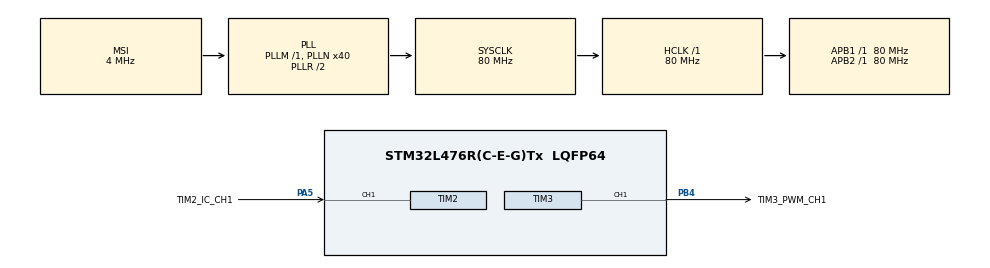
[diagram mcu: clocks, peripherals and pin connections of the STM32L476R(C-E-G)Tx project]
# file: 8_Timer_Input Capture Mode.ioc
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Mcu.Family=STM32L4
Mcu.Name=STM32L476R(C-E-G)Tx
Mcu.Package=LQFP64
NVIC.PriorityGroup=NVIC_PRIORITYGROUP_4
NVIC.TIM2_IRQn=true\:0\:0\:false\:false\:true\:true\:true\:true
PA5.GPIO_Label=TIM2_IC_CH1
PA5.Signal=S_TIM2_CH1
PB4\ (NJTRST).GPIO_Label=TIM3_PWM_CH1
PB4\ (NJTRST).Signal=S_TIM3_CH1
ProjectManager.HeapSize=0x200
ProjectManager.StackSize=0x400
ProjectManager.TargetToolchain=STM32CubeIDE
RCC.AHBFreq_Value=80000000
RCC.APB1Freq_Value=80000000
RCC.APB1TimFreq_Value=80000000
RCC.APB2Freq_Value=80000000
RCC.APB2TimFreq_Value=80000000
RCC.CortexFreq_Value=80000000
RCC.HCLKFreq_Value=80000000
RCC.HSE_VALUE=8000000
RCC.HSI_VALUE=16000000
RCC.LSE_VALUE=32768
RCC.MSI_VALUE=4000000
RCC.PLLN=40
RCC.SYSCLKFreq_VALUE=80000000
RCC.SYSCLKSource=RCC_SYSCLKSOURCE_PLLCLK
RCC.VCOOutputFreq_Value=160000000
SH.S_TIM2_CH1.0=TIM2_CH1,Input_Capture1_from_TI1
SH.S_TIM3_CH1.0=TIM3_CH1,PWM Generation1 CH1
TIM2.Channel-Input_Capture1_from_TI1=TIM_CHANNEL_1
TIM2.Period=4294967295
TIM2.Prescaler=80-1
TIM3.Channel-PWM\ Generation1\ CH1=TIM_CHANNEL_1
TIM3.Period=1000
TIM3.Prescaler=79
TIM3.Pulse-PWM\ Generation1\ CH1=500
VP_TIM2_VS_ClockSourceINT.Mode=Internal
VP_TIM3_VS_ClockSourceINT.Mode=Internal
board=custom

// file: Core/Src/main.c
/* USER CODE BEGIN Header */
/**
  ******************************************************************************
  * @file           : main.c
  * @brief          : Main program body
  ******************************************************************************
  * @attention
  *
  * Copyright (c) 2023 STMicroelectronics.
  * All rights reserved.
  *
  * This software is licensed under terms that can be found in the LICENSE file
  * in the root directory of this software component.
  * If no LICENSE file comes with this software, it is provided AS-IS.
  *
  ******************************************************************************
  */

  /****************************************************************************
	This project could serve the following functionalities according to the Input capture configuration
	for Timer 2:

	- Compute PWM Frequency generated by Timer 3 for that you should
	  1_ Set Timer 2 polarity to rising edge:
	     sConfigIC.ICPolarity = TIM_INPUTCHANNELPOLARITY_RISING;
	  2_ Use the IC_callback function as follows:
	  	 void HAL_TIM_IC_CaptureCallback(TIM_HandleTypeDef *htim)
{
	x+=1;
	if (htim->Channel == HAL_TIM_ACTIVE_CHANNEL_1)
	{
		if (Is_First_Captured==0) // if the first rising edge is not captured
		{
			IC_Val1 = HAL_TIM_ReadCapturedValue(htim, TIM_CHANNEL_1); // read the first value
			Is_First_Captured = 1;  // set the first captured as true
		}

		else   // If the first rising edge is captured, now we will capture the second edge
		{
			IC_Val2 = HAL_TIM_ReadCapturedValue(htim, TIM_CHANNEL_1);  // read second value

			if (IC_Val2 > IC_Val1)
			{
				Difference = IC_Val2-IC_Val1;
			}

			else if (IC_Val1 > IC_Val2)
			{
				Difference = (0xffffffff - IC_Val1) + IC_Val2; // or we can use: Difference = abs(IC_Val2-IC_Val1) without the if and else conditions
			}

			float refClock = TIM2_CLK/(TIM2_PRESCALER + 1);

			frequency = refClock/Difference; //// Cause PWM_Periode = TIM tick delay(period) * (Timer2 Second Captured tick value - Timer2 First Captured tick value)

			__HAL_TIM_SET_COUNTER(htim, 0);  // reset the counter
			Is_First_Captured = 0; // set it back to false
		}
	}
}

	- Compute PWM "ON" width (or duty cycle) generated by Timer 3 for that you should
		1_ Set Timer 2 polarity to both edges:
			sConfigIC.ICPolarity = TIM_INPUTCHANNELPOLARITY_BOTHEDGE;
		2_ Use the previous IC_callback function as follows:
	  	 void HAL_TIM_IC_CaptureCallback(TIM_HandleTypeDef *htim)
{
	x+=1;
	if (htim->Channel == HAL_TIM_ACTIVE_CHANNEL_1)
	{
		if (Is_First_Captured==0) // if the first rising edge is captured
		{
			IC_Val1 = HAL_TIM_ReadCapturedValue(htim, TIM_CHANNEL_1); // read the first value
			Is_First_Captured = 1;  // set the first captured as true
		}

		else   // If the first rising edge is already captured, now we will capture the second edge
		{
			IC_Val2 = HAL_TIM_ReadCapturedValue(htim, TIM_CHANNEL_1);  // read second value

			if (IC_Val2 > IC_Val1)
			{
				Difference = IC_Val2-IC_Val1;
			}

			else if (IC_Val1 > IC_Val2)
			{
				Difference = (0xffffffff - IC_Val1) + IC_Val2; // or we can use: Difference = abs(IC_Val2-IC_Val1) without the if and else conditions
			}

			float ref_period = (TIM2_PRESCALER + 1)/TIM2_CLK;

			ON_width = ref_period*Difference; //// Cause PWM_Periode = TIM tick delay(period) * (Timer2 Second Captured tick value - Timer2 First Captured tick value)
			Duty_cycle = Difference / TIM2->ARR // here we are computing the duty cycle.

			__HAL_TIM_SET_COUNTER(htim, 0);  // reset the counter
			Is_First_Captured = 0; // set it back to false
		}
	}
}

 PS:
 - In both techniques we can set timer counter to 0 once we get the first trigger
 Then capture the counter value in the second input capture trigger.
 - Note that using Input PWM mode (Combined channels section in CubeMX) on Timer 2 ensure measuring the PWM signal width and frequency
 with the same configuration. Refer to this tutorial: https://www.youtube.com/watch?v=P6211ic2N_s&list=PLfIJKC1ud8gjLZBzjE3kKBMDEH_lUc428&index=4

  ******************************************************************************
  */

/* USER CODE END Header */
#include "main.h"

TIM_HandleTypeDef htim2;
TIM_HandleTypeDef htim3;

/* USER CODE BEGIN PV */
#define TIM2_CLK 8000000 // TIM2_CLK
#define TIM2_PRESCALER 79 // TIM2_PRE
int count = 0;

//Those parameters are set constant and they will serve reference frequency calculation (TIM2 frequency) according to : Frequency = TIM2_CLK / (1 + TIM2_PRE)

//We are using Timer2 in input capture mode to compute an external frequency (Timer3)

/* USER CODE END PV */

void SystemClock_Config(void);
static void MX_GPIO_Init(void);
static void MX_TIM2_Init(void);
static void MX_TIM3_Init(void);
/* USER CODE BEGIN PFP */

//HAL_TIM_IC_CaptureCallback function declaration

void HAL_TIM_IC_CaptureCallback( TIM_HandleTypeDef *htim );

/* USER CODE END PFP */

int main(void)
{

  /* MCU Configuration--------------------------------------------------------*/

  /* Reset of all peripherals, Initializes the Flash interface and the Systick. */
  HAL_Init();

  /* Configure the system clock */
  SystemClock_Config();

  /* Initialize all configured peripherals */
  MX_GPIO_Init();
  MX_TIM2_Init();
  MX_TIM3_Init();
  /* USER CODE BEGIN 2 */
  HAL_TIM_PWM_Start(&htim3, TIM_CHANNEL_1);// Lunch the Timer 3 generating PWM signal with a fix duty cycle = 0.5 and a frequency set to 1Mhz
  HAL_TIM_IC_Start(&htim2, TIM_CHANNEL_1);// Start the timer 2 responsible of capturing the rising edges of the generated PWM signal using the
  //Callback function. Which will enable frequency calculation according to the following equation: frequency  = ref_frequency/(First_Rising-Second_Rising)

  /* USER CODE END 2 */

  /* Infinite loop */
  while (1)
  {

  }
}

void SystemClock_Config(void)
{
  RCC_OscInitTypeDef RCC_OscInitStruct = {0};
  RCC_ClkInitTypeDef RCC_ClkInitStruct = {0};

  /** Configure the main internal regulator output voltage
  */
  if (HAL_PWREx_ControlVoltageScaling(PWR_REGULATOR_VOLTAGE_SCALE1) != HAL_OK)
  {
    Error_Handler();
  }

  /** Initializes the RCC Oscillators according to the specified parameters
  * in the RCC_OscInitTypeDef structure.
  */
  RCC_OscInitStruct.OscillatorType = RCC_OSCILLATORTYPE_MSI;
  RCC_OscInitStruct.MSIState = RCC_MSI_ON;
  RCC_OscInitStruct.MSICalibrationValue = 0;
  RCC_OscInitStruct.MSIClockRange = RCC_MSIRANGE_6;
  RCC_OscInitStruct.PLL.PLLState = RCC_PLL_ON;
  RCC_OscInitStruct.PLL.PLLSource = RCC_PLLSOURCE_MSI;
  RCC_OscInitStruct.PLL.PLLM = 1;
  RCC_OscInitStruct.PLL.PLLN = 40;
  RCC_OscInitStruct.PLL.PLLP = RCC_PLLP_DIV7;
  RCC_OscInitStruct.PLL.PLLQ = RCC_PLLQ_DIV2;
  RCC_OscInitStruct.PLL.PLLR = RCC_PLLR_DIV2;
  if (HAL_RCC_OscConfig(&RCC_OscInitStruct) != HAL_OK)
  {
    Error_Handler();
  }

  /** Initializes the CPU, AHB and APB buses clocks
  */
  RCC_ClkInitStruct.ClockType = RCC_CLOCKTYPE_HCLK|RCC_CLOCKTYPE_SYSCLK
                              |RCC_CLOCKTYPE_PCLK1|RCC_CLOCKTYPE_PCLK2;
  RCC_ClkInitStruct.SYSCLKSource = RCC_SYSCLKSOURCE_PLLCLK;
  RCC_ClkInitStruct.AHBCLKDivider = RCC_SYSCLK_DIV1;
  RCC_ClkInitStruct.APB1CLKDivider = RCC_HCLK_DIV1;
  RCC_ClkInitStruct.APB2CLKDivider = RCC_HCLK_DIV1;

  if (HAL_RCC_ClockConfig(&RCC_ClkInitStruct, FLASH_LATENCY_4) != HAL_OK)
  {
    Error_Handler();
  }
}

static void MX_TIM2_Init(void)
{

  TIM_ClockConfigTypeDef sClockSourceConfig = {0};
  TIM_MasterConfigTypeDef sMasterConfig = {0};
  TIM_IC_InitTypeDef sConfigIC = {0};

  htim2.Instance = TIM2;
  htim2.Init.Prescaler = 80-1;
  htim2.Init.CounterMode = TIM_COUNTERMODE_UP;
  htim2.Init.Period = 4294967295;
  htim2.Init.ClockDivision = TIM_CLOCKDIVISION_DIV1;
  htim2.Init.AutoReloadPreload = TIM_AUTORELOAD_PRELOAD_DISABLE;
  if (HAL_TIM_Base_Init(&htim2) != HAL_OK)
  {
    Error_Handler();
  }
  sClockSourceConfig.ClockSource = TIM_CLOCKSOURCE_INTERNAL;
  if (HAL_TIM_ConfigClockSource(&htim2, &sClockSourceConfig) != HAL_OK)
  {
    Error_Handler();
  }
  if (HAL_TIM_IC_Init(&htim2) != HAL_OK)
  {
    Error_Handler();
  }
  sMasterConfig.MasterOutputTrigger = TIM_TRGO_RESET;
  sMasterConfig.MasterSlaveMode = TIM_MASTERSLAVEMODE_DISABLE;
  if (HAL_TIMEx_MasterConfigSynchronization(&htim2, &sMasterConfig) != HAL_OK)
  {
    Error_Handler();
  }
  sConfigIC.ICPolarity = TIM_INPUTCHANNELPOLARITY_RISING;
  sConfigIC.ICSelection = TIM_ICSELECTION_DIRECTTI;
  sConfigIC.ICPrescaler = TIM_ICPSC_DIV1;
  sConfigIC.ICFilter = 0;
  if (HAL_TIM_IC_ConfigChannel(&htim2, &sConfigIC, TIM_CHANNEL_1) != HAL_OK)
  {
    Error_Handler();
  }

}

static void MX_TIM3_Init(void)
{

  TIM_ClockConfigTypeDef sClockSourceConfig = {0};
  TIM_MasterConfigTypeDef sMasterConfig = {0};
  TIM_OC_InitTypeDef sConfigOC = {0};

  htim3.Instance = TIM3;
  htim3.Init.Prescaler = 79;
  htim3.Init.CounterMode = TIM_COUNTERMODE_UP;
  htim3.Init.Period = 1000;
  htim3.Init.ClockDivision = TIM_CLOCKDIVISION_DIV1;
  htim3.Init.AutoReloadPreload = TIM_AUTORELOAD_PRELOAD_DISABLE;
  if (HAL_TIM_Base_Init(&htim3) != HAL_OK)
  {
    Error_Handler();
  }
  sClockSourceConfig.ClockSource = TIM_CLOCKSOURCE_INTERNAL;
  if (HAL_TIM_ConfigClockSource(&htim3, &sClockSourceConfig) != HAL_OK)
  {
    Error_Handler();
  }
  if (HAL_TIM_PWM_Init(&htim3) != HAL_OK)
  {
    Error_Handler();
  }
  sMasterConfig.MasterOutputTrigger = TIM_TRGO_RESET;
  sMasterConfig.MasterSlaveMode = TIM_MASTERSLAVEMODE_DISABLE;
  if (HAL_TIMEx_MasterConfigSynchronization(&htim3, &sMasterConfig) != HAL_OK)
  {
    Error_Handler();
  }
  sConfigOC.OCMode = TIM_OCMODE_PWM1;
  sConfigOC.Pulse = 500;
  sConfigOC.OCPolarity = TIM_OCPOLARITY_HIGH;
  sConfigOC.OCFastMode = TIM_OCFAST_DISABLE;
  if (HAL_TIM_PWM_ConfigChannel(&htim3, &sConfigOC, TIM_CHANNEL_1) != HAL_OK)
  {
    Error_Handler();
  }
  HAL_TIM_MspPostInit(&htim3);

}

static void MX_GPIO_Init(void)
{

  /* GPIO Ports Clock Enable */
  __HAL_RCC_GPIOA_CLK_ENABLE();
  __HAL_RCC_GPIOB_CLK_ENABLE();

}

/* USER CODE BEGIN 4 */

int x = 0 ;
uint32_t IC_Val1 = 0;
uint32_t IC_Val2 = 0;
uint32_t Difference = 0;
int Is_First_Captured = 0;

/* Measure Frequency */
float frequency = 0;

void HAL_TIM_IC_CaptureCallback(TIM_HandleTypeDef *htim)
{
	x+=1;
	if (htim->Channel == HAL_TIM_ACTIVE_CHANNEL_1)
	{
		if (Is_First_Captured==0) // if the first rising edge is not captured
		{
			IC_Val1 = HAL_TIM_ReadCapturedValue(htim, TIM_CHANNEL_1); // read the first value
			Is_First_Captured = 1;  // set the first captured as true
		}

		else   // If the first rising edge is captured, now we will capture the second edge
		{
			IC_Val2 = HAL_TIM_ReadCapturedValue(htim, TIM_CHANNEL_1);  // read second value

			if (IC_Val2 > IC_Val1)
			{
				Difference = IC_Val2-IC_Val1;
			}

			else if (IC_Val1 > IC_Val2)
			{
				Difference = (0xffffffff - IC_Val1) + IC_Val2; // or we can use: Difference = abs(IC_Val2-IC_Val1) without the if and else conditions
			}

			float refClock = TIM2_CLK/(TIM2_PRESCALER + 1);

			frequency = refClock/Difference; //// Cause PWM_Periode = TIM tick delay(period) * (Timer2 Second Captured tick value - Timer2 First Captured tick value)

			__HAL_TIM_SET_COUNTER(htim, 0);  // reset the counter
			Is_First_Captured = 0; // set it back to false
		}
	}
}

/* USER CODE END 4 */

void Error_Handler(void)
{
  __disable_irq();
  while (1)
  {
  }
}
